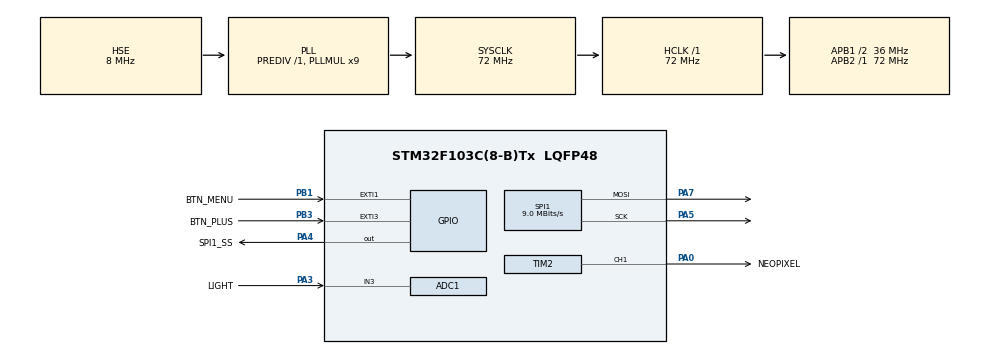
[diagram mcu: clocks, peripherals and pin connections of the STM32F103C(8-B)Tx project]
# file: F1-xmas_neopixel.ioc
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ADC1.Channel-0\#ChannelRegularConversion=ADC_CHANNEL_3
ADC1.NbrOfConversionFlag=1
ADC1.Rank-0\#ChannelRegularConversion=1
ADC1.SamplingTime-0\#ChannelRegularConversion=ADC_SAMPLETIME_1CYCLE_5
ADC1.master=1
Dma.Request0=TIM2_CH1
Dma.TIM2_CH1.0.Direction=DMA_MEMORY_TO_PERIPH
Dma.TIM2_CH1.0.Instance=DMA1_Channel5
Dma.TIM2_CH1.0.MemDataAlignment=DMA_MDATAALIGN_BYTE
Dma.TIM2_CH1.0.MemInc=DMA_MINC_ENABLE
Dma.TIM2_CH1.0.Mode=DMA_CIRCULAR
Dma.TIM2_CH1.0.PeriphDataAlignment=DMA_PDATAALIGN_HALFWORD
Dma.TIM2_CH1.0.PeriphInc=DMA_PINC_DISABLE
Dma.TIM2_CH1.0.Priority=DMA_PRIORITY_VERY_HIGH
Mcu.Family=STM32F1
Mcu.Name=STM32F103C(8-B)Tx
Mcu.Package=LQFP48
NVIC.DMA1_Channel5_IRQn=true\:0\:0\:false\:false\:false\:false
NVIC.EXTI1_IRQn=true\:0\:0\:false\:false\:false\:true
NVIC.EXTI3_IRQn=true\:0\:0\:false\:false\:false\:true
NVIC.PriorityGroup=NVIC_PRIORITYGROUP_4
PA0-WKUP.GPIO_Label=NEOPIXEL
PA0-WKUP.GPIO_Speed=GPIO_SPEED_FREQ_LOW
PA0-WKUP.Signal=S_TIM2_CH1_ETR
PA13.Mode=Serial_Wire
PA13.Signal=SYS_JTMS-SWDIO
PA14.Mode=Serial_Wire
PA14.Signal=SYS_JTCK-SWCLK
PA3.GPIO_Label=LIGHT
PA3.Signal=ADCx_IN3
PA4.GPIO_Label=SPI1_SS
PA4.Signal=GPIO_Output
PA5.Mode=TX_Only_Simplex_Unidirect_Master
PA5.Signal=SPI1_SCK
PA7.Mode=TX_Only_Simplex_Unidirect_Master
PA7.Signal=SPI1_MOSI
PB1.GPIO_Label=BTN_MENU
PB1.GPIO_ModeDefaultEXTI=GPIO_MODE_IT_RISING_FALLING
PB1.GPIO_PuPd=GPIO_PULLUP
PB1.Signal=GPXTI1
PB3.GPIO_Label=BTN_PLUS
PB3.GPIO_ModeDefaultEXTI=GPIO_MODE_IT_RISING_FALLING
PB3.GPIO_PuPd=GPIO_PULLUP
PB3.Signal=GPXTI3
PD0-OSC_IN.Mode=HSE-External-Oscillator
PD0-OSC_IN.Signal=RCC_OSC_IN
PD1-OSC_OUT.Mode=HSE-External-Oscillator
PD1-OSC_OUT.Signal=RCC_OSC_OUT
ProjectManager.HeapSize=0x200
ProjectManager.StackSize=0x400
ProjectManager.TargetToolchain=SW4STM32
RCC.ADCPresc=RCC_ADCPCLK2_DIV6
RCC.AHBFreq_Value=72000000
RCC.APB1CLKDivider=RCC_HCLK_DIV2
RCC.APB1Freq_Value=36000000
RCC.APB1TimFreq_Value=72000000
RCC.APB2Freq_Value=72000000
RCC.APB2TimFreq_Value=72000000
RCC.HCLKFreq_Value=72000000
RCC.PLLMUL=RCC_PLL_MUL9
RCC.PLLSourceVirtual=RCC_PLLSOURCE_HSE
RCC.SYSCLKFreq_VALUE=72000000
RCC.SYSCLKSource=RCC_SYSCLKSOURCE_PLLCLK
RCC.USBFreq_Value=72000000
SH.ADCx_IN3.0=ADC1_IN3,IN3
SH.S_TIM2_CH1_ETR.0=TIM2_CH1,PWM Generation1 CH1
SPI1.BaudRatePrescaler=SPI_BAUDRATEPRESCALER_8
SPI1.CalculateBaudRate=9.0 MBits/s
SPI1.Direction=SPI_DIRECTION_2LINES
SPI1.Mode=SPI_MODE_MASTER
SPI1.VirtualType=VM_MASTER
TIM2.Channel-PWM\ Generation1\ CH1=TIM_CHANNEL_1
TIM2.Period=89
TIM2.Prescaler=0
VP_TIM2_VS_ClockSourceINT.Mode=Internal
board=custom

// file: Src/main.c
/**
  ******************************************************************************
  * @file           : main.c
  * @brief          : Main program body
  ******************************************************************************
  ** This notice applies to any and all portions of this file
  * that are not between comment pairs USER CODE BEGIN and
  * USER CODE END. Other portions of this file, whether
  * inserted by the user or by software development tools
  * are owned by their respective copyright owners.
  *
  * COPYRIGHT(c) 2018 STMicroelectronics
  *
  * Redistribution and use in source and binary forms, with or without modification,
  * are permitted provided that the following conditions are met:
  *   1. Redistributions of source code must retain the above copyright notice,
  *      this list of conditions and the following disclaimer.
  *   2. Redistributions in binary form must reproduce the above copyright notice,
  *      this list of conditions and the following disclaimer in the documentation
  *      and/or other materials provided with the distribution.
  *   3. Neither the name of STMicroelectronics nor the names of its contributors
  *      may be used to endorse or promote products derived from this software
  *      without specific prior written permission.
  *
  * THIS SOFTWARE IS PROVIDED BY THE COPYRIGHT HOLDERS AND CONTRIBUTORS "AS IS"
  * AND ANY EXPRESS OR IMPLIED WARRANTIES, INCLUDING, BUT NOT LIMITED TO, THE
  * IMPLIED WARRANTIES OF MERCHANTABILITY AND FITNESS FOR A PARTICULAR PURPOSE ARE
  * DISCLAIMED. IN NO EVENT SHALL THE COPYRIGHT HOLDER OR CONTRIBUTORS BE LIABLE
  * FOR ANY DIRECT, INDIRECT, INCIDENTAL, SPECIAL, EXEMPLARY, OR CONSEQUENTIAL
  * DAMAGES (INCLUDING, BUT NOT LIMITED TO, PROCUREMENT OF SUBSTITUTE GOODS OR
  * SERVICES; LOSS OF USE, DATA, OR PROFITS; OR BUSINESS INTERRUPTION) HOWEVER
  * CAUSED AND ON ANY THEORY OF LIABILITY, WHETHER IN CONTRACT, STRICT LIABILITY,
  * OR TORT (INCLUDING NEGLIGENCE OR OTHERWISE) ARISING IN ANY WAY OUT OF THE USE
  * OF THIS SOFTWARE, EVEN IF ADVISED OF THE POSSIBILITY OF SUCH DAMAGE.
  *
  ******************************************************************************
  */
#include "main.h"
#include "stm32f1xx_hal.h"

/* USER CODE BEGIN Includes */
#include "start.h"

/* USER CODE END Includes */

ADC_HandleTypeDef hadc1;

SPI_HandleTypeDef hspi1;

TIM_HandleTypeDef htim2;
DMA_HandleTypeDef hdma_tim2_ch1;

/* USER CODE BEGIN PV */
/* Private variables ---------------------------------------------------------*/

/* USER CODE END PV */

void SystemClock_Config(void);
static void MX_GPIO_Init(void);
static void MX_DMA_Init(void);
static void MX_TIM2_Init(void);
static void MX_SPI1_Init(void);
static void MX_ADC1_Init(void);

void HAL_TIM_MspPostInit(TIM_HandleTypeDef *htim);

/* USER CODE BEGIN PFP */
/* Private function prototypes -----------------------------------------------*/

/* USER CODE END PFP */

int main(void)
{

  /* MCU Configuration----------------------------------------------------------*/

  /* Reset of all peripherals, Initializes the Flash interface and the Systick. */
  HAL_Init();

  /* Configure the system clock */
  SystemClock_Config();

  /* Initialize all configured peripherals */
  MX_GPIO_Init();
  MX_DMA_Init();
  MX_TIM2_Init();
  MX_SPI1_Init();
  MX_ADC1_Init();
  /* USER CODE BEGIN 2 */
  setup();

  /* USER CODE END 2 */

  /* Infinite loop */
  /* USER CODE BEGIN WHILE */
  while (1)
  {
	  loop();
  /* USER CODE END WHILE */

  }

}

void SystemClock_Config(void)
{

  RCC_OscInitTypeDef RCC_OscInitStruct;
  RCC_ClkInitTypeDef RCC_ClkInitStruct;
  RCC_PeriphCLKInitTypeDef PeriphClkInit;

    /**Initializes the CPU, AHB and APB busses clocks
    */
  RCC_OscInitStruct.OscillatorType = RCC_OSCILLATORTYPE_HSE;
  RCC_OscInitStruct.HSEState = RCC_HSE_ON;
  RCC_OscInitStruct.HSEPredivValue = RCC_HSE_PREDIV_DIV1;
  RCC_OscInitStruct.HSIState = RCC_HSI_ON;
  RCC_OscInitStruct.PLL.PLLState = RCC_PLL_ON;
  RCC_OscInitStruct.PLL.PLLSource = RCC_PLLSOURCE_HSE;
  RCC_OscInitStruct.PLL.PLLMUL = RCC_PLL_MUL9;
  if (HAL_RCC_OscConfig(&RCC_OscInitStruct) != HAL_OK)
  {
    _Error_Handler(__FILE__, __LINE__);
  }

    /**Initializes the CPU, AHB and APB busses clocks
    */
  RCC_ClkInitStruct.ClockType = RCC_CLOCKTYPE_HCLK|RCC_CLOCKTYPE_SYSCLK
                              |RCC_CLOCKTYPE_PCLK1|RCC_CLOCKTYPE_PCLK2;
  RCC_ClkInitStruct.SYSCLKSource = RCC_SYSCLKSOURCE_PLLCLK;
  RCC_ClkInitStruct.AHBCLKDivider = RCC_SYSCLK_DIV1;
  RCC_ClkInitStruct.APB1CLKDivider = RCC_HCLK_DIV2;
  RCC_ClkInitStruct.APB2CLKDivider = RCC_HCLK_DIV1;

  if (HAL_RCC_ClockConfig(&RCC_ClkInitStruct, FLASH_LATENCY_2) != HAL_OK)
  {
    _Error_Handler(__FILE__, __LINE__);
  }

  PeriphClkInit.PeriphClockSelection = RCC_PERIPHCLK_ADC;
  PeriphClkInit.AdcClockSelection = RCC_ADCPCLK2_DIV6;
  if (HAL_RCCEx_PeriphCLKConfig(&PeriphClkInit) != HAL_OK)
  {
    _Error_Handler(__FILE__, __LINE__);
  }

    /**Configure the Systick interrupt time
    */
  HAL_SYSTICK_Config(HAL_RCC_GetHCLKFreq()/1000);

    /**Configure the Systick
    */
  HAL_SYSTICK_CLKSourceConfig(SYSTICK_CLKSOURCE_HCLK);

  /* SysTick_IRQn interrupt configuration */
  HAL_NVIC_SetPriority(SysTick_IRQn, 0, 0);
}

/* ADC1 init function */
static void MX_ADC1_Init(void)
{

  ADC_ChannelConfTypeDef sConfig;

    /**Common config
    */
  hadc1.Instance = ADC1;
  hadc1.Init.ScanConvMode = ADC_SCAN_DISABLE;
  hadc1.Init.ContinuousConvMode = DISABLE;
  hadc1.Init.DiscontinuousConvMode = DISABLE;
  hadc1.Init.ExternalTrigConv = ADC_SOFTWARE_START;
  hadc1.Init.DataAlign = ADC_DATAALIGN_RIGHT;
  hadc1.Init.NbrOfConversion = 1;
  if (HAL_ADC_Init(&hadc1) != HAL_OK)
  {
    _Error_Handler(__FILE__, __LINE__);
  }

    /**Configure Regular Channel
    */
  sConfig.Channel = ADC_CHANNEL_3;
  sConfig.Rank = ADC_REGULAR_RANK_1;
  sConfig.SamplingTime = ADC_SAMPLETIME_1CYCLE_5;
  if (HAL_ADC_ConfigChannel(&hadc1, &sConfig) != HAL_OK)
  {
    _Error_Handler(__FILE__, __LINE__);
  }

}

/* SPI1 init function */
static void MX_SPI1_Init(void)
{

  /* SPI1 parameter configuration*/
  hspi1.Instance = SPI1;
  hspi1.Init.Mode = SPI_MODE_MASTER;
  hspi1.Init.Direction = SPI_DIRECTION_2LINES;
  hspi1.Init.DataSize = SPI_DATASIZE_8BIT;
  hspi1.Init.CLKPolarity = SPI_POLARITY_LOW;
  hspi1.Init.CLKPhase = SPI_PHASE_1EDGE;
  hspi1.Init.NSS = SPI_NSS_SOFT;
  hspi1.Init.BaudRatePrescaler = SPI_BAUDRATEPRESCALER_8;
  hspi1.Init.FirstBit = SPI_FIRSTBIT_MSB;
  hspi1.Init.TIMode = SPI_TIMODE_DISABLE;
  hspi1.Init.CRCCalculation = SPI_CRCCALCULATION_DISABLE;
  hspi1.Init.CRCPolynomial = 10;
  if (HAL_SPI_Init(&hspi1) != HAL_OK)
  {
    _Error_Handler(__FILE__, __LINE__);
  }

}

/* TIM2 init function */
static void MX_TIM2_Init(void)
{

  TIM_ClockConfigTypeDef sClockSourceConfig;
  TIM_MasterConfigTypeDef sMasterConfig;
  TIM_OC_InitTypeDef sConfigOC;

  htim2.Instance = TIM2;
  htim2.Init.Prescaler = 0;
  htim2.Init.CounterMode = TIM_COUNTERMODE_UP;
  htim2.Init.Period = 89;
  htim2.Init.ClockDivision = TIM_CLOCKDIVISION_DIV1;
  htim2.Init.AutoReloadPreload = TIM_AUTORELOAD_PRELOAD_DISABLE;
  if (HAL_TIM_Base_Init(&htim2) != HAL_OK)
  {
    _Error_Handler(__FILE__, __LINE__);
  }

  sClockSourceConfig.ClockSource = TIM_CLOCKSOURCE_INTERNAL;
  if (HAL_TIM_ConfigClockSource(&htim2, &sClockSourceConfig) != HAL_OK)
  {
    _Error_Handler(__FILE__, __LINE__);
  }

  if (HAL_TIM_PWM_Init(&htim2) != HAL_OK)
  {
    _Error_Handler(__FILE__, __LINE__);
  }

  sMasterConfig.MasterOutputTrigger = TIM_TRGO_RESET;
  sMasterConfig.MasterSlaveMode = TIM_MASTERSLAVEMODE_DISABLE;
  if (HAL_TIMEx_MasterConfigSynchronization(&htim2, &sMasterConfig) != HAL_OK)
  {
    _Error_Handler(__FILE__, __LINE__);
  }

  sConfigOC.OCMode = TIM_OCMODE_PWM1;
  sConfigOC.Pulse = 0;
  sConfigOC.OCPolarity = TIM_OCPOLARITY_HIGH;
  sConfigOC.OCFastMode = TIM_OCFAST_DISABLE;
  if (HAL_TIM_PWM_ConfigChannel(&htim2, &sConfigOC, TIM_CHANNEL_1) != HAL_OK)
  {
    _Error_Handler(__FILE__, __LINE__);
  }

  HAL_TIM_MspPostInit(&htim2);

}

static void MX_DMA_Init(void)
{
  /* DMA controller clock enable */
  __HAL_RCC_DMA1_CLK_ENABLE();

  /* DMA interrupt init */
  /* DMA1_Channel5_IRQn interrupt configuration */
  HAL_NVIC_SetPriority(DMA1_Channel5_IRQn, 0, 0);
  HAL_NVIC_EnableIRQ(DMA1_Channel5_IRQn);

}

/** Configure pins as
        * Analog
        * Input
        * Output
        * EVENT_OUT
        * EXTI
*/
static void MX_GPIO_Init(void)
{

  GPIO_InitTypeDef GPIO_InitStruct;

  /* GPIO Ports Clock Enable */
  __HAL_RCC_GPIOD_CLK_ENABLE();
  __HAL_RCC_GPIOA_CLK_ENABLE();
  __HAL_RCC_GPIOB_CLK_ENABLE();

  /*Configure GPIO pin Output Level */
  HAL_GPIO_WritePin(SPI1_SS_GPIO_Port, SPI1_SS_Pin, GPIO_PIN_RESET);

  /*Configure GPIO pin : SPI1_SS_Pin */
  GPIO_InitStruct.Pin = SPI1_SS_Pin;
  GPIO_InitStruct.Mode = GPIO_MODE_OUTPUT_PP;
  GPIO_InitStruct.Pull = GPIO_NOPULL;
  GPIO_InitStruct.Speed = GPIO_SPEED_FREQ_LOW;
  HAL_GPIO_Init(SPI1_SS_GPIO_Port, &GPIO_InitStruct);

  /*Configure GPIO pins : BTN_MENU_Pin BTN_PLUS_Pin */
  GPIO_InitStruct.Pin = BTN_MENU_Pin|BTN_PLUS_Pin;
  GPIO_InitStruct.Mode = GPIO_MODE_IT_RISING_FALLING;
  GPIO_InitStruct.Pull = GPIO_PULLUP;
  HAL_GPIO_Init(GPIOB, &GPIO_InitStruct);

  /* EXTI interrupt init*/
  HAL_NVIC_SetPriority(EXTI1_IRQn, 0, 0);
  HAL_NVIC_EnableIRQ(EXTI1_IRQn);

  HAL_NVIC_SetPriority(EXTI3_IRQn, 0, 0);
  HAL_NVIC_EnableIRQ(EXTI3_IRQn);

}

void _Error_Handler(char *file, int line)
{
  while(1)
  {
  }
}

/************************ (C) COPYRIGHT STMicroelectronics *****END OF FILE****/
